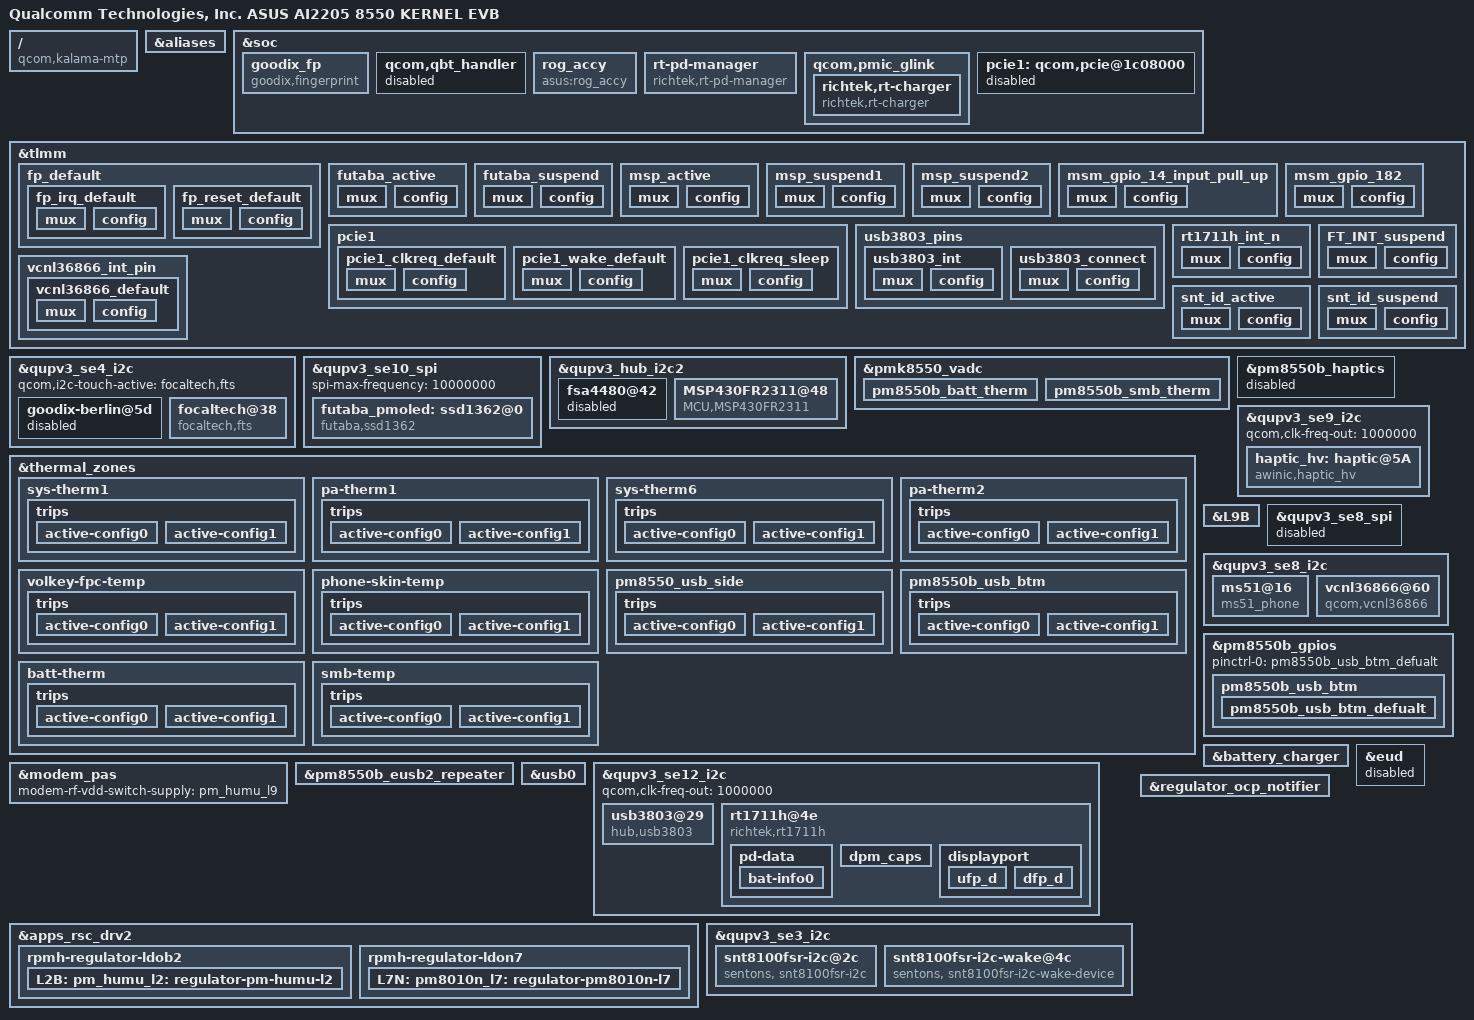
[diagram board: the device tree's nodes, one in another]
/dts-v1/;
/plugin/;

#include "kalama-mtp.dtsi"
#include <dt-bindings/clock/qcom,rpmh.h>

/ {
	model = "Qualcomm Technologies, Inc. ASUS AI2205 8550 KERNEL EVB";
	compatible = "qcom,kalama-mtp", "qcom,kalama", "qcom,mtp";
	qcom,msm-id = <519 0x10000>, <536 0x10000>, <519 0x20000>, <536 0x20000>;
	qcom,board-id = <30 0>;
};

&aliases {
		i2c1 = "/soc/qcom,qupv3_1_geni_se@ac0000/i2c@a80000";
		i2c2 = "/soc/qcom,qupv3_1_geni_se@ac0000/i2c@a90000";
		i2c7 = "/soc/qcom,qupv3_2_geni_se@8c0000/i2c@880000";
		spi0 = "/soc/qcom,qupv3_2_geni_se@8c0000/spi@888000";
};

//ASUS BSP Fingerprint +++
&soc {
	goodix_fp {
		compatible = "goodix,fingerprint";
		fp-gpio-irq = <&tlmm 40 0x00>;
		fp-gpio-reset = <&tlmm 72 0x0>;
		fp-gpio-cs = <&tlmm 39 0x0>;
		vcc-supply = <&L5M>;
		asus-fp,vcc-voltage=<3150000 3300000>;
		pinctrl-names = "fp_default";
		pinctrl-0 = <&fp_irq_default &fp_reset_default>;
		status = "okay";
 	};

	//Disable qcom default FP setting
	qcom,qbt_handler {
		status = "disable";
	};
};

&tlmm{
	fp_default {
		fp_irq_default: fp_irq_default {
			mux {
				pins = "gpio40";
				function = "gpio";
			};
			config {
				pins = "gpio40";
				bias-disable;
				drive-strength = <8>;
			};
		};

		fp_reset_default: fp_reset_default {
			mux {
				pins = "gpio72";
				function = "gpio";
			};
			config {
				pins = "gpio72";
				bias-pull-down;
				drive-strength = <8>;
			};
		};
	};
};
//ASUS BSP Fingerprint ---

//ASUS BSP Touch +++

&qupv3_se4_i2c {
	#address-cells = <1>;
	#size-cells = <0>;

	status = "ok";

	qcom,i2c-touch-active = "focaltech,fts";

	goodix-berlin@5d {
		status = "disable";
	};

	focaltech@38 {
		compatible = "focaltech,fts";
		reg = <0x38>;
		interrupt-parent = <&tlmm>;
		interrupts = <25 0x2008>;
		focaltech,reset-gpio = <&tlmm 24 0x00>;
		focaltech,irq-gpio = <&tlmm 25 0x2008>;
		focaltech,max-touch-number = <10>;
		focaltech,display-coords = <0 0 1080 2448>;
		focaltech,touch-type = "primary";

		vdd-supply = <&L14B>;
		vcc_i2c-supply = <&L4B>;

		pinctrl-names = "pmx_ts_active", "pmx_ts_suspend","pmx_ts_release";
		pinctrl-0 = <&ts_active>;
		pinctrl-1 = <&ts_int_suspend &ts_reset_suspend>;
		pinctrl-2 = <&ts_release>;
		//panel = <&dsi_ams667uu07_fhd_plus_dsc_cmd &dsi_ams678_fhd_plus_dsc_cmd &dsi_ams678_er2_fhd_plus_dsc_cmd>
	};
};

//ASUS BSP Touch ---

/*    ====================================
 *    overlay for kalama-pinctrl.dtsi - start
 *    ====================================
 */

&tlmm {
	futaba_active: futaba_active {
		mux {
			pins = "gpio4", "gpio62", "gpio70", "gpio71";
			function = "gpio";
		};
		config {
			pins = "gpio4", "gpio62", "gpio70", "gpio71";
			drive-strength = <8>;
			bias-pull-up;
		};
	};

	futaba_suspend: futaba_suspend {
		mux {
			pins = "gpio4", "gpio62", "gpio70", "gpio71";
			function = "gpio";
		};
		config {
			pins = "gpio4", "gpio62", "gpio70", "gpio71";
			drive-strength = <2>;
			bias-pull-down;
		};
	};
};

// MCU porting
&tlmm{
	msp_active: msp_active{
		mux {
			pins = "gpio59", "gpio87", "gpio58", "gpio126", "gpio6", "gpio73", "gpio7", "gpio8";
			function = "gpio";
		};
		config {
			pins = "gpio59", "gpio87", "gpio58", "gpio126", "gpio6", "gpio73", "gpio7", "gpio8";
			drive-strength = <2>; /* 2 MA */
			bias-pull-up;
			input-enable;
		};
	};

	msp_suspend1: msp_suspend1{
		mux {
			pins = "gpio87", "gpio58", "gpio126";
			function = "gpio";
		};
		config {
			pins = "gpio87", "gpio58", "gpio126";
			drive-strength = <2>; /* 2 MA */
			bias-pull-down;
		};
	};

	msp_suspend2: msp_suspend2{
		mux {
			pins = "gpio6", "gpio73", "gpio7", "gpio8";
			function = "gpio";
		};
		config {
			pins = "gpio6", "gpio73", "gpio7", "gpio8";
			drive-strength = <2>; /* 2 MA */
			bias-disable;
		};
	};
};

// for pcie1 not used
&tlmm{
	pcie1 {
		pcie1_clkreq_default: pcie1_clkreq_default {
			mux {
				pins = "gpio98";
				function = "pcie1_clk_req_n";
			};

			config {
				pins = "gpio98";
				drive-strength = <2>;
				bias-pull-down;
			};
		};

		pcie1_wake_default: pcie1_wake_default {
			mux {
				pins = "gpio99";
				function = "gpio";
			};

			config {
				pins = "gpio99";
				drive-strength = <2>;
				bias-pull-down;
			};
		};

		pcie1_clkreq_sleep: pcie1_clkreq_sleep {
			mux {
				pins = "gpio98";
				function = "gpio";
			};

			config {
				pins = "gpio98";
				drive-strength = <2>;
				bias-pull-down;
			};
		};
	};
};

/*    ====================================
 *    overlay for kalama-pinctrl.dtsi - end
 *    ====================================
 */

/*    ====================================
 *    overlay for kalama-qupv3.dtsi - start
 *    ====================================
 */

/* for PMOLED */
&qupv3_se10_spi {
	status = "ok";
	spi-max-frequency = <10000000>;

	futaba_pmoled: ssd1362@0 {
		compatible = "futaba,ssd1362";
		reg = <0>;
		spi-max-frequency = <10000000>;
		futaba,reset-gpio = <&tlmm 70 0>;
		futaba,dc-gpio = <&tlmm 62 0>;
		futaba,pwren-gpio = <&tlmm 4 0>;
		futaba,vci-gpio = <&tlmm 71 0>;

		// to determine if there is PMOLED on the board
		asus,hardware-stage = "evb";

		pinctrl-names = "futaba_active", "futaba_suspend";
		pinctrl-0 = <&futaba_active>;
		pinctrl-1 = <&futaba_suspend>;
	};
};

&qupv3_hub_i2c2 {
	status = "ok";

	fsa4480@42 {
		status = "disable";
	};

	MSP430FR2311@48 {
		compatible = "MCU,MSP430FR2311";
		reg = <0x48>;
		//vcc_s4a_1p8-supply = <&pm8150_s4>;
		//vcc_l10a_3p3-supply = <&pm8350c_l11>;
		//pinctrl-names = "mcu_active", "mcu_suspend";
		//pinctrl-0 = <&mcu_pin_test_enable &mcu_pin_int_enable &mcu_power_enable>;
		//pinctrl-1 = <&mcu_pin_test_disable &mcu_pin_int_disable &mcu_power_disable>;
		//gpios = <&tlmm 10 0>, <&tlmm 59 0>, <&tlmm 17 0>;
		pinctrl-names = "msp_active", "msp_suspend1", "msp_suspend2";
		pinctrl-0 = <&msp_active>;
		pinctrl-1 = <&msp_suspend1>;
		pinctrl-2 = <&msp_suspend2>;

		MCU,mcureset-gpios = <&pm8550vs_g_gpios 4 0x0>;
		MCU,mcutest-gpios = <&tlmm 10 0x00>;
		//MCU,mcuwakeup-gpios = <&pm8550b_gpios 8 0x0>;
		MCU,mcuint-gpios = <&tlmm 59 0x00>;
		MCU,power-gpios = <&tlmm 17 0x00>;
		angle-vdd-supply = <&L8B>; //1.8v
		MCU,slave_address = <0x48>;

		drm,type = "primary";
		hw-id0-gpio = <&tlmm 6 0x0>;
		hw-id1-gpio = <&tlmm 73 0x0>;
		hw-id2-gpio = <&tlmm 7 0x0>;
		hw-id3-gpio = <&tlmm 8 0x0>;
		prj-id0-gpio = <&tlmm 87 0x0>;
		prj-id1-gpio = <&tlmm 58 0x0>;
		prj-id2-gpio = <&tlmm 126 0x0>;
	};
};

/*    ====================================
 *    overlay for kalama-qupv3.dtsi - end
 *    ====================================
 */

&pmk8550_vadc {
	pm8550b_batt_therm {
		reg = <PM8550B_ADC5_GEN3_AMUX_THM1_BATT_THERM_100K_PU>;
		label = "pm8550b_batt_therm";
		qcom,ratiometric;
		qcom,hw-settle-time = <200>;
		qcom,pre-scaling = <1 1>;
		qcom,adc-tm-type = <1>;
	};

	pm8550b_smb_therm {
		reg = <PM8550B_ADC5_GEN3_AMUX_THM3_SMB_TEMP_V_100K_PU>;
		label = "pm8550b_smb_therm";
		qcom,ratiometric;
		qcom,hw-settle-time = <200>;
		qcom,pre-scaling = <1 1>;
		qcom,adc-tm-type = <1>;
	};
};

&thermal_zones {
	sys-therm1 {
		polling-delay-passive = <0>;
		polling-delay = <0>;
		thermal-sensors = <&pmk8550_vadc PM8550_ADC5_GEN3_AMUX_THM1_100K_PU>;
		trips {
			active-config0 {
				temperature = <125000>;
				hysteresis = <1000>;
				type = "passive";
			};
			active-config1 {
				temperature = <125000>;
				hysteresis = <1000>;
				type = "passive";
			};
		};
	};

	pa-therm1 {
		polling-delay-passive = <0>;
		polling-delay = <0>;
		thermal-sensors = <&pmk8550_vadc PM8550_ADC5_GEN3_AMUX_THM2_100K_PU>;
		trips {
			active-config0 {
				temperature = <125000>;
				hysteresis = <1000>;
				type = "passive";
			};
			active-config1 {
				temperature = <125000>;
				hysteresis = <1000>;
				type = "passive";
			};
		};
	};

	sys-therm6 {
		polling-delay-passive = <0>;
		polling-delay = <0>;
		thermal-sensors = <&pmk8550_vadc PM8550_ADC5_GEN3_AMUX_THM3_100K_PU>;
		trips {
			active-config0 {
				temperature = <125000>;
				hysteresis = <1000>;
				type = "passive";
			};
			active-config1 {
				temperature = <125000>;
				hysteresis = <1000>;
				type = "passive";
			};
		};
	};

	pa-therm2 {
		polling-delay-passive = <0>;
		polling-delay = <0>;
		thermal-sensors = <&pmk8550_vadc PM8550_ADC5_GEN3_AMUX_THM4_100K_PU>;
		trips {
			active-config0 {
				temperature = <125000>;
				hysteresis = <1000>;
				type = "passive";
			};
			active-config1 {
				temperature = <125000>;
				hysteresis = <1000>;
				type = "passive";
			};
		};
	};

	volkey-fpc-temp {
		polling-delay-passive = <0>;
		polling-delay = <0>;
		thermal-sensors = <&pmk8550_vadc PM8550_ADC5_GEN3_AMUX_THM5_100K_PU>;
		trips {
			active-config0 {
				temperature = <125000>;
				hysteresis = <1000>;
				type = "passive";
			};
			active-config1 {
				temperature = <125000>;
				hysteresis = <1000>;
				type = "passive";
			};
		};
	};

	phone-skin-temp {
		polling-delay-passive = <0>;
		polling-delay = <0>;
		thermal-sensors = <&pmk8550_vadc PM8550B_ADC5_GEN3_AMUX_THM6_GPIO10_100K_PU>;
		trips {
			active-config0 {
				temperature = <125000>;
				hysteresis = <1000>;
				type = "passive";
			};
			active-config1 {
				temperature = <125000>;
				hysteresis = <1000>;
				type = "passive";
			};
		};
	};

//ASUS_BSP : Add for charger +++
	pm8550_usb_side {
		polling-delay-passive = <0>;
		polling-delay = <0>;
		thermal-sensors = <&pmk8550_vadc PM8550_ADC5_GEN3_AMUX_THM6_GPIO2_100K_PU>;
		trips {
			active-config0 {
				temperature = <125000>;
				hysteresis = <1000>;
				type = "passive";
			};
			active-config1 {
				temperature = <125000>;
				hysteresis = <1000>;
				type = "passive";
			};
		};
	};

	pm8550b_usb_btm {
		polling-delay-passive = <0>;
		polling-delay = <0>;
		thermal-sensors = <&pmk8550_vadc PM8550B_ADC5_GEN3_AMUX3_GPIO6_100K_PU>;
		trips {
			active-config0 {
				temperature = <125000>;
				hysteresis = <1000>;
				type = "passive";
			};
			active-config1 {
				temperature = <125000>;
				hysteresis = <1000>;
				type = "passive";
			};
		};
	};	
//ASUS_BSP : Add for charger ---
	batt-therm {
		polling-delay-passive = <0>;
		polling-delay = <0>;
		thermal-sensors = <&pmk8550_vadc PM8550B_ADC5_GEN3_AMUX_THM1_BATT_THERM_100K_PU>;
		trips {
			active-config0 {
				temperature = <125000>;
				hysteresis = <1000>;
				type = "passive";
			};
			active-config1 {
				temperature = <125000>;
				hysteresis = <1000>;
				type = "passive";
			};
		};
	};

	smb-temp {
		polling-delay-passive = <0>;
		polling-delay = <0>;
		thermal-sensors = <&pmk8550_vadc PM8550B_ADC5_GEN3_AMUX_THM3_SMB_TEMP_V_100K_PU>;
		trips {
			active-config0 {
				temperature = <125000>;
				hysteresis = <1000>;
				type = "passive";
			};
			active-config1 {
				temperature = <125000>;
				hysteresis = <1000>;
				type = "passive";
			};
		};
	};
};

//ASUS_BSP: aw haptic +++
&pm8550b_haptics {
	status = "disabled";
};

&qupv3_se9_i2c {
	status = "ok";
	qcom,clk-freq-out = <1000000>;
	#address-cells = <1>;
	#size-cells = <0>;

	haptic_hv: haptic@5A {
		compatible = "awinic,haptic_hv";
		reg = <0x5A>;
		irq-gpio = <&tlmm 14 0>;
		reset-gpio = <&tlmm 13 0>;
		pinctrl-names = "irq_active";
		pinctrl-0 = <&msm_gpio_14_input_pull_up &msm_gpio_182>;
		f0_pre = < 1300 >;
		mode = /bits/ 8 < 5 >;
		f0_cali_percent = /bits/ 8 < 15 >;

/*******************************aw869x*******************************/
		aw869x_max_bst_vol = /bits/ 8 <0x1f>;
		aw869x_cont_drv_lev = /bits/ 8 < 105 >;
		aw869x_cont_drv_lvl_ov = /bits/ 8 < 125 >;
		aw869x_cont_td = < 0x009A >;
		aw869x_cont_zc_thr = < 0x0FF1 >;
		aw869x_cont_num_brk = /bits/ 8 < 3 >;
		aw869x_f0_coeff = < 260 >; /*Don't modify it 2.604167*/
		aw869x_duration_time = /bits/ 8 < 20 30 60 >;
		aw869x_f0_trace_parameter = /bits/ 8 < 0x05 0x03 0x02 0x0f >;
		aw869x_bemf_config = /bits/ 8 < 0x10 0x08 0x03 0xf8 >;
		aw869x_tset = /bits/ 8 < 0x12 >;
		aw869x_r_spare = /bits/ 8 < 0x68 >;
		aw869x_bstdbg = /bits/ 8 < 0x30 0xeb 0xd4 0 0 0 >;
		aw869x_trig_config = /bits/ 8 < 0 1 1 1 2 0 1 1 1 2 0 1 1 1 2 >;
		aw869x_bst_vol_default = < 8500 >;

/******************************aw869xx*******************************/
		aw869xx_gain_bypass = /bits/ 8 < 1 >;
		aw869xx_max_bst_vol = /bits/ 8 <0x3f>;
		aw869xx_brk_bst_md = /bits/ 8 < 0 >;
		aw869xx_cont_drv1_lvl = /bits/ 8 < 0x7F >;
		aw869xx_cont_drv2_lvl = /bits/ 8 < 0x36 >;
		aw869xx_cont_brk_time = /bits/ 8 < 0x08 >;
		aw869xx_cont_tset = /bits/ 8 < 0x06 >;
		aw869xx_cont_bemf_set = /bits/ 8 < 0x02 >;
		aw869xx_cont_drv_width = /bits/ 8 < 0x6A >;
		aw869xx_cont_track_margin = /bits/ 8 < 0x12 >;
		aw869xx_cont_brk_gain = /bits/ 8 < 0x08 >;
		aw869xx_cont_bst_brk_gain = /bits/ 8 < 0x05 >;
		aw869xx_cont_wait_num = /bits/ 8 < 0x06 >;
		aw869xx_cont_drv1_time = /bits/ 8 < 0x04 >;
		aw869xx_cont_drv2_time = /bits/ 8 < 0x14 >;
		aw869xx_duration_time = /bits/ 8 < 20 30 60 >;
		aw869xx_sine_array = /bits/ 8 < 0x05 0xB2 0xFF 0xEF >;
		aw869xx_d2s_gain = /bits/ 8 < 0x04 >;
		aw869xx_bstcfg = /bits/ 8 < 0x20 0x24 0x96 0x40 0x11 >;
		aw869xx_trig_config = /bits/ 8 < 0 0 0 1 0 2 0 0
						 0 0 0 1 0 2 0 0
						 0 0 0 1 0 2 0 0 >;
		aw869xx_bst_vol_default = < 8500 >;
		/* aw869xx_is_enabled_auto_bst; */
		/* aw869xx_is_enabled_i2s; */
		/* aw869xx_is_enabled_one_wire; */

/******************************aw8671x*******************************/
		aw8671x_gain_bypass = /bits/ 8 < 1 >;
		aw8671x_brk_bst_md = /bits/ 8 < 0 >;
		aw8671x_cont_drv1_lvl = /bits/ 8 < 0x7F >;
		aw8671x_cont_drv2_lvl = /bits/ 8 < 0x36 >;
		aw8671x_cont_brk_time = /bits/ 8 < 0x08 >;
		aw8671x_cont_tset = /bits/ 8 < 0x06 >;
		aw8671x_cont_bemf_set = /bits/ 8 < 0x02 >;
		aw8671x_cont_drv_width = /bits/ 8 < 0x6A >;
		aw8671x_cont_track_margin = /bits/ 8 < 0x12 >;
		aw8671x_cont_brk_gain = /bits/ 8 < 0x08 >;
		aw8671x_cont_bst_brk_gain = /bits/ 8 < 0x05 >;
		aw8671x_cont_wait_num = /bits/ 8 < 0x06 >;
		aw8671x_cont_drv1_time = /bits/ 8 < 0x04 >;
		aw8671x_cont_drv2_time = /bits/ 8 < 0x14 >;
		aw8671x_duration_time = /bits/ 8 < 20 30 60 >;
		aw8671x_d2s_gain = /bits/ 8 < 0x04 >;
		aw8671x_trig_config = /bits/ 8 < 0 0 0 1 0 2 0 0
						 0 0 0 1 0 2 0 0
						 0 0 0 1 0 2 0 0 >;
		aw8671x_bst_vol_default = < 6336 >;
		/* aw8671x_is_enabled_auto_bst; */
		/* aw8671x_is_enabled_i2s; */
		/* aw8671x_is_enabled_one_wire; */

/******************************aw8692x*******************************/
		aw8692x_gain_bypass = /bits/ 8 < 1 >;
		aw8692x_cont_drv1_lvl = /bits/ 8 < 0x7F >;
		aw8692x_cont_drv2_lvl = /bits/ 8 < 0x50 >;
		aw8692x_cont_drv1_time = /bits/ 8 < 0x04 >;
		aw8692x_cont_drv2_time = /bits/ 8 < 0x06 >;
		aw8692x_cont_drv_width = /bits/ 8 < 0x9C >;
		aw8692x_cont_track_margin = /bits/ 8 < 0x0C >;
		aw8692x_cont_brk_gain = /bits/ 8 < 0x08 >;
		aw8692x_cont_bst_brk_gain = /bits/ 8 < 0x05 >;
		aw8692x_cont_wait_num = /bits/ 8 < 0x06 >;
		aw8692x_cont_brk_time = /bits/ 8 < 0x08 >;
		aw8692x_brk_bst_md = /bits/ 8 < 0 >;
		aw8692x_cont_tset = /bits/ 8 < 0x06 >;
		aw8692x_cont_bemf_set = /bits/ 8 < 0x02 >;
		aw8692x_duration_time = /bits/ 8 < 20 30 60 >;
		aw8692x_d2s_gain = /bits/ 8 < 0x04 >;
		aw8692x_trig_config = /bits/ 8 < 0 0 1 3 0 2 0 1
						 0 0 1 4 0 2 0 1
						 0 0 0 1 0 2 0 0 >;
		aw8692x_bst_vol_default = < 8000 >;
		/* aw8692x_is_enabled_auto_bst; */
		/* aw8692x_is_enabled_one_wire; */
	};
};

&tlmm {

	/* GPIO_14 : INTERRUPT_N */
	msm_gpio_14_input_pull_up: msm_gpio_14_input_pull_up {
		mux {
			 pins = "gpio14";
			 function = "gpio";
		};

		config {
			pins = "gpio14";
			drive-strength = <2>;
			bias-pull-up;
			input-enable;
		};
	};

	/* GPIO_182 : trig */
	msm_gpio_182: msm_gpio_182 {
		mux {
			 pins = "gpio182";
			 function = "gpio";
		};

		config {
			pins = "gpio182";
			drive-strength = <2>;
			bias-pull-down;
			output-low;
		};
	};
};
//ASUS_BSP: aw haptic ---

// ASUS_BSP+++ Phone Antenna

&L9B {
	regulator-min-microvolt = <2800000>;
	regulator-max-microvolt = <2800000>;
	qcom,init-voltage = <2800000>;
};

&modem_pas {
	modem-rf-vdd-switch-supply = <&pm_humu_l9>;
};
// ASUS_BSP--- Phone Antenna

//AUSS_BSP: aura light +++
&qupv3_se8_spi {
    status = "disable";
};

//ASUS BSP ACCY +++
&soc {
	rog_accy {
		compatible = "asus:rog_accy";
		status = "okay";

		accy,vph_ctrl = <&tlmm 50 0x0>;
		accy,type = "primary";
	};
};
//ASUS BSP ACCY ---

&qupv3_se8_i2c {
    status = "ok";
    ms51@16 {
        compatible = "ms51_phone";
        reg = <0x16>;

        nuvoton,logo_5p0_en = <&pm8550b_gpios 9 0x0>;
        nuvoton,wakeup_pin = <&tlmm 137 0>;
        nuvoton,hw_stage = <5>;
    };
};
//AUSS_BSP: aura light ---

//ASUS_BSP : Add for charger +++
&pm8550b_gpios {
	pinctrl-0 = <&pm8550b_usb_btm_defualt>;
	pinctrl-names = "default";
	
	pm8550b_usb_btm {
		pm8550b_usb_btm_defualt: pm8550b_usb_btm_defualt {
			pins = "gpio6";
			function = "func2";
			input-enable;
			bias-disable;
		};
	};
};

&battery_charger {
	io-channels = <&pmk8550_vadc PM8550_ADC5_GEN3_AMUX_THM6_GPIO2_100K_PU>,
			 <&pmk8550_vadc PM8550B_ADC5_GEN3_AMUX3_GPIO6_100K_PU>,
			 <&pmk8550_vadc PM8550_ADC5_GEN3_AMUX_THM5_100K_PU>,
			 <&pmk8550_vadc PM8550B_ADC5_GEN3_AMUX_THM1_BATT_THERM_100K_PU>;
	io-channel-names ="pm8550_amux_thm6_gpio2", "pm8550b_amux3_gpio6", "pm8550_amux_thm5", "pm8550b_amux_thm1_batt_therm";
};
//ASUS_BSP : Add for charger ---

&eud {
	status = "disabled";
};

&pm8550b_eusb2_repeater {
	qcom,param-override-seq =
		/* <value reg_offset> */
		/* Adjust HS trasmit amplitude */
		<0xd 0x51
		/* Disconnect Threshold - EUSB2_TUNE_HSDISC */
		 0x4 0x53
		/* Squelch detection threshold */
		 0x3 0x54
		/* Tx pre-emphasis tuning */
		 0x2 0x57>;
	qcom,param-override-seq-BTM =
		/* <value reg_offset> */
		/* Adjust HS trasmit amplitude */
		<0xd 0x51
		/* Disconnect Threshold - EUSB2_TUNE_HSDISC */
		 0x4 0x53
		/* Squelch detection threshold */
		 0x3 0x54
		/* Tx pre-emphasis tuning */
		 0x7 0x57>;
};

//ASUS_BSP: usb mux +++
&usb0 {
	MUX1_OE = <&tlmm 91 0x0>;
	MUX2_OE = <&pm8550b_gpios 7 GPIO_ACTIVE_LOW>;//BHS_GPIO_07
	MUX2_SEL = <&tlmm 124 0x0>;
	MUX3_OE = <&tlmm 53 0x0>;
	MUX3_SEL = <&tlmm 54 0x0>;
};
//ASUS_BSP: usb mux ---

//ASUS_BSP: usb hub +++
&qupv3_se12_i2c {
	status = "ok";
	usb3803@29 {
		compatible = "hub,usb3803";
		reg = <0x29>;

		clock-names = "hub_ref_clk";
		clocks = <&rpmhcc RPMH_LN_BB_CLK4>;

		HUB_BYPASS = <&tlmm 122 0x0>;
		HUB_RESET = <&tlmm 123 0x0>;
		HUB_CONNECT = <&tlmm 121 0x0>;

		pinctrl-names = "hub_int", "hub_connect";
		pinctrl-0 = <&usb3803_int>;
		pinctrl-1 = <&usb3803_connect>;
	};
};

&tlmm{
	usb3803_pins {
		usb3803_int: usb3803_int {
			mux {
				pins = "gpio46";
				function = "gpio";
			};
			config {
				pins = "gpio46";
				bias-disable;
				drive-strength = <2>;
			};
		};

		usb3803_connect: usb3803_connect {
			mux {
				pins = "gpio121";
				function = "gpio";
			};
			config {
				pins = "gpio121";
				bias-pull-up;
				output-high;
			};
		};
	};
};
//ASUS_BSP: usb hub ---

//ASUS BSP Richtek TypeC PD +++
&qupv3_se12_i2c {
	status = "okay";
	qcom,clk-freq-out = <1000000>;
	rt1711h@4e {
		compatible = "richtek,rt1711h";
		reg = <0x4e>;
		tcpc-dual,supported_modes = <0>; /* 0: dfp/ufp, */
						 /* 1: dfp, 2: ufp */
		rt-tcpc,name = "typec"; /* tcpc_device's name */
		rt-tcpc,role_def = <5>; /* 0: Unknown, 1: SNK, 2: SRC */
					/* 3: DRP, 4: Try.SRC, 5: Try.SNK */
		rt-tcpc,rp_level = <0>; /* 0: Default, 1: 1.5, 2: 3.0 */
		rt-tcpc,vconn_supply = <0>;  /* 0: Never, 1: Always, */
					     /* 2: EMarkOnly, 3: StartOnly */
		rt1711pd,intr_gpio = <&tlmm 47 0x0>;
		rt1711pd,intr_gpio_num = <47>;
		pinctrl-names = "rt1711h_int_n";
		pinctrl-0 = <&rt1711h_int_n>;
		pd-data {
			pd,vid = <0x29cf>;
			pd,pid = <0x1711>;
			pd,source-cap-ext = /bits/ 8 <0xcf 0x29 0x11 0x17
						      0x00 0x00 0x00 0x00
						      0x00 0x00 0x00 0x00
						      0x00 0x00 0x00 0x00
						      0x00 0x00 0x00 0x00
						      0x00 0x00 0x01 0x02
						      0x00>;
			pd,mfrs = "RichtekTCPC";

			/*
			 *	VSAFE5V = 0, MAX_POWER = 1, CUSTOM = 2,
			 *	MAX_POWER_LV = 0x21, MAX_POWER_LVIC = 0x31
			 *	MAX_POWER_HV = 0x41, MAX_POWER_HVIC = 0x51
			 */
			pd,charging_policy = <0x31>;

			/*
			 * Fixed 5V, 500 mA <0x00019032>
			 * Fixed 5V, 1A <0x00019064>
			 * Fixed 5V, 2A <0x000190c8>
			 * Fixed 5V, 3A <0x0001912c>
			 * Fixed 9V, 500 mA <0x0002d032>
			 * Fixed 9V, 1A <0x0002d064>
			 * Fixed 9V, 2A <0x0002d0c8>
			 * Fixed 9V, 3A <0x0002d12c>
			 * Variable 5-9V, 1A <0x8642d064>
			 * Variable 5-9V, 2A <0x8642d0c8>
			 * Variable 5-9V, 3A <0x8642d12c>
			 */
			pd,source-pdo-size = <1>;
			pd,source-pdo-data = <0x00019032>;
			pd,sink-pdo-size = <1>;
			pd,sink-pdo-data = <0x000190c8>;

			/*
			 * No DP, host + device
			 *	pd,id-vdo-size = <6>;
			 *	pd,id-vdo-data = <0xd14029cf 0x0 0x17110000
						  0x61000000 0x0 0x41000000>;
			 * With DP
			 *	pd,id-vdo-size = <6>;
			 *	pd,id-vdo-data = <0xd54029cf 0x0 0x17110000
						  0x61000000 0x0 0x41000000>;
			 */

			pd,id-vdo-size = <6>;
			pd,id-vdo-data = <0xd14029cf 0x0 0x17110000
					  0x61000000 0x0 0x41000000>;

			bat,nr = <1>;
			pd,country_nr = <0>;

			bat-info0 {
				bat,vid = <0x29cf>;
				bat,pid = <0x1711>;
				bat,mfrs = "bat1";
				bat,design_cap = <3000>;
			};

			//bat-info1 {
			//	bat,vid = <0x8abc>;
			//	bat,pid = <0x5234>;
			//	bat,mfrs = "bat2";
			//	bat,design_cap = <4000>;
			//};

			//country0 {
			//	pd,country_code = <0x5457>;
			//	pd,country_len = <2>; /* max len = 26 */
			//	pd,country_data = <0xff 0xff>;
			//};

			//country1 {
			//	pd,country_code = <0x5553>;
			//	pd,country_len = <3>; /* max len = 26 */
			//	pd,country_data = <0xf1 0xf2 0xf3>;
			//};
		};
		dpm_caps {
			local_dr_power;
			local_dr_data;
			//local_ext_power;
			local_usb_comm;
			//local_usb_suspend;
			//local_high_cap;
			//local_give_back;
			local_no_suspend;
			//local_vconn_supply;

			//attempt_discover_cable_dfp;
			attempt_enter_dp_mode;
			attempt_discover_cable;
			attempt_discover_id;

			/* 0: disable, 1: prefer_snk, 2: prefer_src */
			pr_check = <0>;
			//pr_reject_as_source;
			//pr_reject_as_sink;
			//pr_check_gp_source;
			//pr_check_gp_sink;

			/* 0: disable, 1: prefer_ufp, 2: prefer_dfp */
			dr_check = <0>;
			//dr_reject_as_dfp;
			//dr_reject_as_ufp;
		};
		displayport {
			/* connection type = "both", "ufp_d", "dfp_d" */
			1st_connection = "dfp_d";
			2nd_connection = "dfp_d";
			signal,dp_v13;
			//signal,dp_gen2;
			//usbr20_not_used;
			typec,receptacle;
			ufp_d {
				//pin_assignment,mode_a;
				//pin_assignment,mode_b;
				//pin_assignment,mode_c;
				//pin_assignment,mode_d;
				//pin_assignment,mode_e;
			};
			dfp_d {
				//pin_assignment,mode_a;
				//pin_assignment,mode_b;
				pin_assignment,mode_c;
				pin_assignment,mode_d;
				pin_assignment,mode_e;
				//pin_assignment,mode_f;
			};
		};
	};
};

&soc {
	rt-pd-manager {
		compatible = "richtek,rt-pd-manager";
	};

	qcom,pmic_glink {
		richtek,rt-charger {
			compatible = "richtek,rt-charger";
			//vconn-supply = <&vconn_5v>;
		};
	};
};

&tlmm {
	rt1711h_int_n: rt1711h_int_n {
		mux {
			pins = "gpio47";
			function = "gpio";
		};

		config {
			pins = "gpio47";
			drive-strength = <2>;
			bias-pull-up;
		};
	};
};
//ASUS BSP Richtek TypeC PD ---

// ASUS_BSP P/L sensor +++ vcnl36866
&qupv3_se8_i2c {
        status = "ok";
        vcnl36866@60 {
               compatible = "qcom,vcnl36866";
               reg = <0x60>;
               pinctrl-names = "alsps_gpio_no_pull";
               pinctrl-0 = <&vcnl36866_default>;
               qcom,alsps-gpio = <&tlmm 16 0x0>;
               vcc_psensor-supply = <&L2B>;
               vcc_psensor_1v8-supply  = <&L1B>;
        };
};

&apps_rsc_drv2 {
       rpmh-regulator-ldob2 {
               L2B: pm_humu_l2: regulator-pm-humu-l2 {
                       regulator-min-microvolt = <3000000>;
                       regulator-max-microvolt = <3300000>;
                       qcom,init-voltage = <3000000>;
               };
       };
       
       rpmh-regulator-ldon7 {
               L7N: pm8010n_l7: regulator-pm8010n-l7 {
                       regulator-min-microvolt = <2800000>;
                       regulator-max-microvolt = <2800000>;
                       qcom,init-voltage = <2800000>;
               };
       };       
};

&tlmm {
       vcnl36866_int_pin {
               vcnl36866_default: vcnl36866_default {
                       mux {
                               pins = "gpio16";
                               function = "gpio";
                       };
                       config {
                               pins = "gpio16";
                               bias-disable = <0>; /* no pull */
                               drive-strength = <4>;
                       };
               };
       };
};
// ASUS_BSP P/L sensor --- vcnl36866

//AUSS_BSP: AirTrigger +++
&qupv3_se3_i2c {
	status = "ok";
	snt8100fsr-i2c@2c {
		reg = <0x2c>;
		compatible = "sentons, snt8100fsr-i2c";
		
		qcom,snt-host1-gpio = <&tlmm 15 0x0>;
		rst_gpios = <&tlmm 12 0x0>;
		snt-id-gpio = <&tlmm 174 GPIO_ACTIVE_HIGH>;
		vcc_grip_2v8-supply = <&L7N>;
		vcc_grip_1v2-supply = <&L11B>;
		vcc_grip_1v8-supply = <&L15B>;
		
		pinctrl-names = "FT_INT_suspend", "snt_id_active", "snt_id_suspend";
		pinctrl-0 = <&FT_INT_suspend>;
		pinctrl-1 = <&snt_id_active>;
		pinctrl-2 = <&snt_id_suspend>;
	};
	snt8100fsr-i2c-wake@4c {
		reg = <0x4c>;
		wake-device = <1>;
		compatible = "sentons, snt8100fsr-i2c-wake-device";
	};
};

&tlmm {
	FT_INT_suspend: FT_INT_suspend {
		mux {
			pins = "gpio15";
			function = "gpio";
		};

		config {
			pins = "gpio15";
			bias-disable = <0>; /* no pull */
			drive-strength = <2>;
		};
	};

	snt_id_active: snt_id_active {
		/* active state */
		mux {
			pins = "gpio174";
			function = "gpio";
		};
		config {
			pins = "gpio174";
			drive-strength = <2>; /* 2 MA */
			bias-pull-up;
		};
	};
	
	snt_id_suspend: snt_id_suspend {
		mux {
			pins = "gpio174";
			function = "gpio";
		};
		config {
			pins = "gpio174";
			bias-pull-down;
			drive-strength = <2>;
		};
	};
};
//AUSS_BSP: AirTrigger ---

//ASUS_BSP: Panel loob12 & ldob13 +++
&regulator_ocp_notifier {
	/delete-property/ periph-1cc-supply;
	/delete-property/ periph-1cd-supply;
	/delete-property/ periph-4c1-supply;
	/delete-property/ periph-4c3-supply;
};
//ASUS_BSP: Panel loob12 & ldob13 ---

// for pcie1 not used
&soc {
	pcie1: qcom,pcie@1c08000 {
		status = "disable";
	};
};
